# CEC1702 register map
Vendor: Microchip Technology; Series: CEC1702Q; File version: 0
CPU: CM4 r1p0, little endian, MPU, FPU, 3 interrupt priority bits, 155 interrupts
Registers are 32-bit, read-write, reset 0x0 unless marked. A register's access mark holds for its fields unless they carry their own. Offsets are from the block's base; [hi:lo] are bit positions; {n}, {i} and the like mark numbered series.

## ADC — This block is designed to convert external analog voltage readings into digital values.
Base 0x40007C00; register names take the prefix ADC_
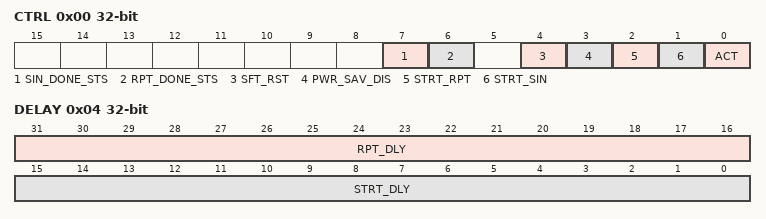
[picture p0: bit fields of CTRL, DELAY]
0x00 CTRL — The ADC Control Register is used to control the behavior of the Analog to Digital Converter.
  [7] SIN_DONE_STS — 0: ADC single-sample conversion is not complete. 1: ADC single-sample conversion is completed. (R/WC)
  [6] RPT_DONE_STS — 0: ADC repeat-sample conversion is not complete. 1: ADC repeat-sample conversion is completed. (R/WC)
  [4] SFT_RST — (SFT_RST) 1: writing one causes a reset of the ADC block hardware (not the registers) 0: writing zero takes the ADC block out of reset
  [3] PWR_SAV_DIS — 0: Power saving feature is enabled. 1: Power saving feature is disabled.
  [2] STRT_RPT — 0: The ADC Repeat Mode is disabled. 1: The ADC Repeat Mode is enabled.
  [1] STRT_SIN — (STRT_SIN) 0: The ADC Single Mode is disabled. 1: The ADC Single Mode is enabled. Note: This bit is self-clearing
  [0] ACT — 0: The ADC is disabled and placed in its lowest power state. 1: ADC block is enabled for operation.
0x04 DELAY — The ADC Delay register determines the delay from setting Start_Repeat in the. ADC Control Register and the start of a conversion cycle. This register also controls the interval between conversion cycles in repeat mode.
  [31:16] RPT_DLY — This field determines the interval between conversion cycles when Start_Repeat is 1.
  [15:0] STRT_DLY — This field determines the starting delay before a conversion cycle is begun when Start_Repeat is written with a 1.
0x08 CHAN_STS — The ADC Status Register indicates whether the ADC has completed a conversion cycle. All bits are cleared by being written with a 1. 0: conversion of the corresponding ADC channel is not complete. 1: conversion of the corresponding ADC channel is complete
  [15:0] STS — All bits are cleared by being written with a '1'. 1=conversion of the corresponding ADC channel is complete; 0=conversion of the corresponding ADC channel is not complete. For enabled single cycles, the SINGLE_DONE_STATUS bit in the. ADC Control Register is also set after all enabled channel conversion are done; for enabled repeat cycles, the REPEAT_DONE_STATUS in the ADC Control Register is also set after all enabled channel conversion are done.
0x0C SNG_EN — The ADC Single Register is used to control which ADC channel is captured during a Single-Sample conversion cycle initiated by the Start_Single bit in the ADC Control Register. APPLICATION NOTE: Do not change the bits in this register in the middle of a conversion cycle to insure proper operation. 0: single cycle conversions for this channel are disabled. 1: single cycle conversions for this channel are enabled
  [15:0] S_EN — Each bit in this field enables the corresponding ADC channel when a single cycle of conversions is started when the. START_SINGLE bit in the ADC Control Register is written with a 1. 1=single cycle conversions for this channel are enabled. 0=single cycle conversions for this channel are disabled. Note: If this register is changed while a conversion.
0x10 REPT_EN — The ADC Repeat Register is used to control which ADC channels are captured during a repeat conversion cycle initiated by the Start_Repeat bit in the ADC Control Register.
  [15:0] R_EN — Each bit in this field enables the corresponding ADC channel for each pass of the Repeated ADC Conversion that is controlled by bit START_REPEAT in the ADC Control Register. 1=repeat conversions for this channel are enabled; 0=repeat conversions for this channel are disabled
{0x14+4i} CHAN_RD[{i}] (i=0..15) — All 16 ADC channels return their results into a 32-bit reading register. In each case the low 10 bits of the reading register return the result of the Analog to Digital conversion and the upper 22 bits return 0.
